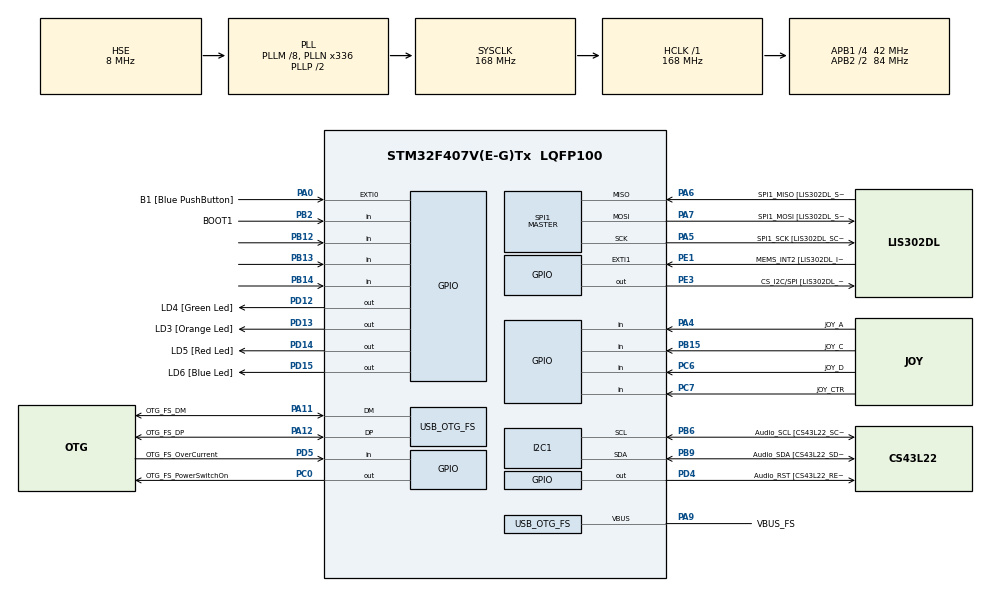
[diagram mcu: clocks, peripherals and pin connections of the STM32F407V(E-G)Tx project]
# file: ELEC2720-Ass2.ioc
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PA11.GPIO_Speed=GPIO_SPEED_FREQ_LOW
PD12.GPIO_Label=LD4 [Green Led]
PH0-OSC_IN.Signal=RCC_OSC_IN
PC10.GPIO_PuPd=GPIO_NOPULL
SPI1.VirtualType=VM_MASTER
PB10.GPIO_PuPd=GPIO_NOPULL
PA10.GPIO_PuPd=GPIO_NOPULL
PC12.Signal=I2S3_SD
PA14.GPIO_Label=SWCLK
PC6.GPIO_Label=JOY_D
PA6.GPIO_Label=SPI1_MISO [LIS302DL_SDO]
PB6.GPIO_Label=Audio_SCL [CS43L22_SCL]
PB13.Signal=GPIO_Input
PC15-OSC32_OUT.GPIO_Label=PC15-OSC32_OUT
PC3.GPIO_Speed=GPIO_SPEED_FREQ_LOW
RCC.SYSCLKSource=RCC_SYSCLKSOURCE_PLLCLK
PA6.GPIO_Mode=GPIO_MODE_AF_PP
PD14.GPIO_Speed=GPIO_SPEED_FREQ_LOW
SPI1.Direction=SPI_DIRECTION_2LINES
PD4.Signal=GPIO_Output
RCC.APB2TimFreq_Value=168000000
PB6.Signal=I2C1_SCL
PC7.Signal=GPIO_Input
PB6.Mode=I2C
PC3.Signal=I2S2_SD
PE1.Signal=GPXTI1
USB_OTG_FS.phy_itface=HCD_PHY_EMBEDDED
PB2.Signal=GPIO_Input
PA5.GPIO_PuPd=GPIO_NOPULL
PD5.GPIO_Mode=GPIO_MODE_INPUT
PD14.GPIO_PuPd=GPIO_NOPULL
PB2.GPIO_PuPd=GPIO_NOPULL
SPI1.CalculateBaudRate-Full_Duplex_Master=42.0 MBits/s
Mcu.Package=LQFP100
PB9.Signal=I2C1_SDA
PB14.GPIO_PuPd=GPIO_PULLUP
PD12.Signal=GPIO_Output
PB9.GPIO_PuPd=GPIO_NOPULL
PA10.Signal=USB_OTG_FS_ID
PC6.GPIO_PuPd=GPIO_PULLUP
RCC.APB2CLKDivider=RCC_HCLK_DIV2
RCC.APB1TimFreq_Value=84000000
PC12.GPIO_PuPd=GPIO_NOPULL
PA6.GPIO_Speed=GPIO_SPEED_FREQ_LOW
PA12.GPIO_PuPd=GPIO_NOPULL
PA4.GPIO_Label=JOY_A
PD15.Signal=GPIO_Output
PC0.PinState=GPIO_PIN_SET
PA5.Mode=Full_Duplex_Master
PA9.GPIO_Label=VBUS_FS
PB6.GPIO_PuPd=GPIO_NOPULL
PC6.Signal=GPIO_Input
PA11.GPIO_Label=OTG_FS_DM
PE1.GPIO_PuPd=GPIO_NOPULL
PC0.Signal=GPIO_Output
RCC.APB1CLKDivider=RCC_HCLK_DIV4
PC14-OSC32_IN.Signal=RCC_OSC32_IN
PA0-WKUP.GPIO_ModeDefaultEXTI=GPIO_MODE_EVT_RISING
PA0-WKUP.GPIO_Label=B1 [Blue PushButton]
PA0-WKUP.Signal=GPXTI0
USB_HOST0.BSP.STBoard=false
PC10.GPIO_Mode=GPIO_MODE_AF_PP
PB10.GPIO_Mode=GPIO_MODE_AF_PP
PA9.Signal=USB_OTG_FS_VBUS
PC7.GPIO_PuPd=GPIO_PULLUP
PB10.Signal=I2S2_CK
PB14.Signal=GPIO_Input
PA5.Signal=SPI1_SCK
PE1.GPIO_Label=MEMS_INT2 [LIS302DL_INT2]
USB_HOST.VirtualModeFS=Cdc
PA7.GPIO_Speed=GPIO_SPEED_FREQ_LOW
PB13.GPIO_PuPd=GPIO_PULLUP
PB2.GPIO_Mode=GPIO_MODE_INPUT
PB15.GPIO_Label=JOY_C
SPI1.Mode=SPI_MODE_MASTER
PD4.GPIO_Speed=GPIO_SPEED_FREQ_LOW
PE3.GPIO_PuPd=GPIO_NOPULL
PH1-OSC_OUT.GPIO_Label=PH1-OSC_OUT
PA13.Mode=Serial_Wire
PC7.GPIO_Label=JOY_CTR
PA4.Signal=GPIO_Input
PC12.GPIO_Mode=GPIO_MODE_AF_PP
PA5.GPIO_Label=SPI1_SCK [LIS302DL_SCL/SPC]
PE3.GPIO_Speed=GPIO_SPEED_FREQ_LOW
PC12.GPIO_Label=I2S3_SD [CS43L22_SDIN]
PA11.Signal=USB_OTG_FS_DM
ProjectManager.HeapSize=0x200
NVIC.PriorityGroup=NVIC_PRIORITYGROUP_0
PE3.Signal=GPIO_Output
PC3.GPIO_Label=PDM_OUT [MP45DT02_DOUT]
PA0-WKUP.GPIO_PuPd=GPIO_NOPULL
PB6.GPIO_Speed=GPIO_SPEED_FREQ_LOW
SPI1.BaudRatePrescaler-Full_Duplex_Master=SPI_BAUDRATEPRESCALER_2
USB_HOST0.BSP.mode=Output
Mcu.Family=STM32F4
PC3.GPIO_Mode=GPIO_MODE_AF_PP
PA6.Mode=Full_Duplex_Master
RCC.CortexFreq_Value=168000000
PB10.GPIO_Speed=GPIO_SPEED_FREQ_LOW
PB6.GPIO_Mode=GPIO_MODE_AF_OD
PD15.GPIO_Speed=GPIO_SPEED_FREQ_LOW
PC10.Signal=I2S3_CK
PA7.GPIO_Mode=GPIO_MODE_AF_PP
PC0.GPIO_Label=OTG_FS_PowerSwitchOn
PA11.Mode=Host_Only
PC10.GPIO_Speed=GPIO_SPEED_FREQ_LOW
PA11.GPIO_PuPd=GPIO_NOPULL
PB15.Signal=GPIO_Input
ProjectManager.StackSize=0x400
SPI1.Mode-Full_Duplex_Master=SPI_MODE_MASTER
PD13.Signal=GPIO_Output
PA12.Signal=USB_OTG_FS_DP
RCC.HCLKFreq_Value=168000000
USB_HOST0.BSP.ip=GPIO
RCC.AHBFreq_Value=168000000
PH0-OSC_IN.Mode=HSE-External-Oscillator
PH0-OSC_IN.GPIO_Label=PH0-OSC_IN
PA9.GPIO_Mode=GPIO_MODE_INPUT
RCC.HSE_VALUE=8000000
PA4.GPIO_PuPd=GPIO_PULLUP
PA6.GPIO_PuPd=GPIO_NOPULL
PC14-OSC32_IN.Mode=LSE-External-Oscillator
PA14.Mode=Serial_Wire
PA10.GPIO_Label=OTG_FS_ID
USB_HOST0.BSP.i2creg=0
PH1-OSC_OUT.Mode=HSE-External-Oscillator
USB_HOST0.BSP.i2caddr=0
PD13.GPIO_Label=LD3 [Orange Led]
PA6.Signal=SPI1_MISO
PB15.GPIO_PuPd=GPIO_PULLUP
USB_HOST.USBH_HandleTypeDef-CDC_FS=hUsbHostFS
PD5.GPIO_Label=OTG_FS_OverCurrent
NVIC.OTG_FS_IRQn=true\:0\:0\:false\:false\:true\:true\:true
PD15.GPIO_PuPd=GPIO_NOPULL
USB_OTG_FS.VirtualMode=Host_Only
PA10.GPIO_Speed=GPIO_SPEED_FREQ_LOW
USB_HOST0.BSP.name=Drive_VBUS_FS
PB9.GPIO_Speed=GPIO_SPEED_FREQ_LOW
PC14-OSC32_IN.GPIO_Label=PC14-OSC32_IN
PC0.GPIO_PuPd=GPIO_NOPULL
PA12.GPIO_Speed=GPIO_SPEED_FREQ_LOW
PB3.GPIO_Label=SWO
PC15-OSC32_OUT.Mode=LSE-External-Oscillator
PD12.GPIO_Speed=GPIO_SPEED_FREQ_LOW
PD15.GPIO_Label=LD6 [Blue Led]
PA7.Mode=Full_Duplex_Master
PB9.GPIO_Label=Audio_SDA [CS43L22_SDA]
PC10.GPIO_Label=I2S3_SCK [CS43L22_SCLK]
USB_HOST0.BSP.solution=PC0
USB_HOST.BSP.number=1
PD5.Signal=GPIO_Input
PE1.GPIO_ModeDefaultEXTI=GPIO_MODE_EVT_RISING
PA9.GPIO_PuPd=GPIO_NOPULL
PA12.GPIO_Label=OTG_FS_DP
PA10.GPIO_Mode=GPIO_MODE_AF_PP
PA13.Signal=SYS_JTMS-SWDIO
PD4.GPIO_PuPd=GPIO_NOPULL
PA9.Mode=Activate_VBUS
PC0.GPIO_Speed=GPIO_SPEED_FREQ_LOW
ProjectManager.TargetToolchain=STM32CubeIDE
PB10.GPIO_Label=CLK_IN [MP45DT02_CLK]
PB9.Mode=I2C
PC15-OSC32_OUT.Signal=RCC_OSC32_OUT
PA7.GPIO_PuPd=GPIO_NOPULL
board=STM32F407G-DISC1
PD13.GPIO_Speed=GPIO_SPEED_FREQ_LOW
RCC.VCOOutputFreq_Value=336000000
PB9.GPIO_Mode=GPIO_MODE_AF_OD
PA12.GPIO_Mode=GPIO_MODE_AF_PP
RCC.APB2Freq_Value=84000000
USB_HOST0.BSP.api=Unknown
PD4.GPIO_Label=Audio_RST [CS43L22_RESET]
PH1-OSC_OUT.Signal=RCC_OSC_OUT
PD13.GPIO_PuPd=GPIO_NOPULL
PD5.GPIO_PuPd=GPIO_NOPULL
PD14.GPIO_Label=LD5 [Red Led]
Mcu.Name=STM32F407V(E-G)Tx
PA13.GPIO_Label=SWDIO
PD14.Signal=GPIO_Output
RCC.48MHZClocksFreq_Value=48000000
PB3.Signal=SYS_JTDO-SWO
RCC.SYSCLKFreq_VALUE=168000000
PA7.GPIO_Label=SPI1_MOSI [LIS302DL_SDA/SDI/SDO]
PA12.Mode=Host_Only
VP_USB_HOST_VS_USB_HOST_CDC_FS.Mode=CDC_FS
PA14.Signal=SYS_JTCK-SWCLK
PB2.GPIO_Label=BOOT1
RCC.HSI_VALUE=16000000
PA5.GPIO_Speed=GPIO_SPEED_FREQ_LOW
RCC.PLLQ=7
RCC.PLLM=8
RCC.PLLN=336
PE3.GPIO_Label=CS_I2C/SPI [LIS302DL_CS_I2C/SPI]
PA11.GPIO_Mode=GPIO_MODE_AF_PP
RCC.APB1Freq_Value=42000000
PA5.GPIO_Mode=GPIO_MODE_AF_PP
PC12.GPIO_Speed=GPIO_SPEED_FREQ_LOW
PB12.Signal=GPIO_Input
PC3.GPIO_PuPd=GPIO_NOPULL
PD12.GPIO_PuPd=GPIO_NOPULL
PA7.Signal=SPI1_MOSI
USB_HOST0.BSP.instance=PC0

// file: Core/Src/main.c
/* USER CODE BEGIN Header */
/**
  ******************************************************************************
  * @file           : main.c
  * @brief          : Main program body
  ******************************************************************************
  * @attention
  *
  * <h2><center>&copy; Copyright (c) 2022 STMicroelectronics.
  * All rights reserved.</center></h2>
  *
  * This software component is licensed by ST under Ultimate Liberty license
  * SLA0044, the "License"; You may not use this file except in compliance with
  * the License. You may obtain a copy of the License at:
  *                             www.st.com/SLA0044
  *
  ******************************************************************************
  */
/* USER CODE END Header */
#include "main.h"
#include "usb_host.h"

/* USER CODE BEGIN PD */
#define DEBOUNCE_INTERVAL 20
/* USER CODE END PD */

I2C_HandleTypeDef hi2c1;

SPI_HandleTypeDef hspi1;

void SystemClock_Config(void);
static void MX_GPIO_Init(void);
static void MX_I2C1_Init(void);
static void MX_SPI1_Init(void);
void MX_USB_HOST_Process(void);

int main(void)
{

  /* MCU Configuration--------------------------------------------------------*/

  /* Reset of all peripherals, Initializes the Flash interface and the Systick. */
  HAL_Init();

  /* Configure the system clock */
  SystemClock_Config();

  /* Initialize all configured peripherals */
  MX_GPIO_Init();
  MX_I2C1_Init();
  MX_SPI1_Init();
  MX_USB_HOST_Init();
  /* USER CODE BEGIN 2 */
  int debounce_counter = 0;
  enum debounceState {LOCKED, RELEASED};
  enum debounceState debounce_state = RELEASED;
  int JoyState = 1;

  /* USER CODE END 2 */
  HAL_GPIO_WritePin(LD4_GPIO_Port, LD4_Pin, 0); // Left LED
  HAL_GPIO_WritePin(LD5_GPIO_Port, LD5_Pin, 0); // Right LED

  /* Infinite loop */
  while (1)
  {
    MX_USB_HOST_Process();

    switch(debounce_state) {
    	case RELEASED:
    	// Read JOY_C only when RELEASED
			JoyState = HAL_GPIO_ReadPin (JOY_C_GPIO_Port, JOY_C_Pin);
			if (JoyState == 0) {
				debounce_state = LOCKED;
			}
		break;

    case LOCKED:
		JoyState = 1; // Manually reset JoyState when LOCKED
		if ( debounce_counter > DEBOUNCE_INTERVAL) {
			debounce_state = RELEASED; // RELEASE after time-out
			debounce_counter = 0;
		}
		else {
			++debounce_counter; // still LOCKED, increase counter
		}
		break;
    }

    if (HAL_GPIO_ReadPin(JOY_CTR_GPIO_Port, JOY_CTR_Pin) == 0) { // Joy Stick: Centre
         HAL_GPIO_WritePin(LD4_GPIO_Port, LD4_Pin, 0);
         HAL_GPIO_WritePin(LD5_GPIO_Port, LD5_Pin, 0);
       }
   	else if (HAL_GPIO_ReadPin(JOY_A_GPIO_Port, JOY_A_Pin) == 0) { // Joy Stick: Left
         HAL_GPIO_WritePin(LD4_GPIO_Port, LD4_Pin, 1);
         HAL_GPIO_WritePin(LD5_GPIO_Port, LD5_Pin, 0);
       }
   	else if (HAL_GPIO_ReadPin(JOY_D_GPIO_Port, JOY_D_Pin) == 0) { // Joy Stick: Right
         HAL_GPIO_WritePin(LD4_GPIO_Port, LD4_Pin, 0);
         HAL_GPIO_WritePin(LD5_GPIO_Port, LD5_Pin, 1);
   	}
   	else if (JoyState == 0) { // Joy Stick: Down
         if (HAL_GPIO_ReadPin(LD4_GPIO_Port, LD4_Pin) == 0 && HAL_GPIO_ReadPin(LD5_GPIO_Port, LD5_Pin) == 0) { // LEDs All off
           HAL_GPIO_WritePin(LD4_GPIO_Port, LD4_Pin, 1);
           HAL_GPIO_WritePin(LD5_GPIO_Port, LD5_Pin, 0);
         }
         else { // One led already on
           HAL_GPIO_TogglePin(LD4_GPIO_Port, LD4_Pin);
           HAL_GPIO_TogglePin(LD5_GPIO_Port, LD5_Pin);
         }
     }
    HAL_Delay(10);

  }
}

void SystemClock_Config(void)
{
  RCC_OscInitTypeDef RCC_OscInitStruct = {0};
  RCC_ClkInitTypeDef RCC_ClkInitStruct = {0};

  /** Configure the main internal regulator output voltage
  */
  __HAL_RCC_PWR_CLK_ENABLE();
  __HAL_PWR_VOLTAGESCALING_CONFIG(PWR_REGULATOR_VOLTAGE_SCALE1);
  /** Initializes the RCC Oscillators according to the specified parameters
  * in the RCC_OscInitTypeDef structure.
  */
  RCC_OscInitStruct.OscillatorType = RCC_OSCILLATORTYPE_HSE;
  RCC_OscInitStruct.HSEState = RCC_HSE_ON;
  RCC_OscInitStruct.PLL.PLLState = RCC_PLL_ON;
  RCC_OscInitStruct.PLL.PLLSource = RCC_PLLSOURCE_HSE;
  RCC_OscInitStruct.PLL.PLLM = 8;
  RCC_OscInitStruct.PLL.PLLN = 336;
  RCC_OscInitStruct.PLL.PLLP = RCC_PLLP_DIV2;
  RCC_OscInitStruct.PLL.PLLQ = 7;
  if (HAL_RCC_OscConfig(&RCC_OscInitStruct) != HAL_OK)
  {
    Error_Handler();
  }
  /** Initializes the CPU, AHB and APB buses clocks
  */
  RCC_ClkInitStruct.ClockType = RCC_CLOCKTYPE_HCLK|RCC_CLOCKTYPE_SYSCLK
                              |RCC_CLOCKTYPE_PCLK1|RCC_CLOCKTYPE_PCLK2;
  RCC_ClkInitStruct.SYSCLKSource = RCC_SYSCLKSOURCE_PLLCLK;
  RCC_ClkInitStruct.AHBCLKDivider = RCC_SYSCLK_DIV1;
  RCC_ClkInitStruct.APB1CLKDivider = RCC_HCLK_DIV4;
  RCC_ClkInitStruct.APB2CLKDivider = RCC_HCLK_DIV2;

  if (HAL_RCC_ClockConfig(&RCC_ClkInitStruct, FLASH_LATENCY_5) != HAL_OK)
  {
    Error_Handler();
  }
}

static void MX_I2C1_Init(void)
{

  hi2c1.Instance = I2C1;
  hi2c1.Init.ClockSpeed = 100000;
  hi2c1.Init.DutyCycle = I2C_DUTYCYCLE_2;
  hi2c1.Init.OwnAddress1 = 0;
  hi2c1.Init.AddressingMode = I2C_ADDRESSINGMODE_7BIT;
  hi2c1.Init.DualAddressMode = I2C_DUALADDRESS_DISABLE;
  hi2c1.Init.OwnAddress2 = 0;
  hi2c1.Init.GeneralCallMode = I2C_GENERALCALL_DISABLE;
  hi2c1.Init.NoStretchMode = I2C_NOSTRETCH_DISABLE;
  if (HAL_I2C_Init(&hi2c1) != HAL_OK)
  {
    Error_Handler();
  }

}

static void MX_SPI1_Init(void)
{

  /* SPI1 parameter configuration*/
  hspi1.Instance = SPI1;
  hspi1.Init.Mode = SPI_MODE_MASTER;
  hspi1.Init.Direction = SPI_DIRECTION_2LINES;
  hspi1.Init.DataSize = SPI_DATASIZE_8BIT;
  hspi1.Init.CLKPolarity = SPI_POLARITY_LOW;
  hspi1.Init.CLKPhase = SPI_PHASE_1EDGE;
  hspi1.Init.NSS = SPI_NSS_SOFT;
  hspi1.Init.BaudRatePrescaler = SPI_BAUDRATEPRESCALER_2;
  hspi1.Init.FirstBit = SPI_FIRSTBIT_MSB;
  hspi1.Init.TIMode = SPI_TIMODE_DISABLE;
  hspi1.Init.CRCCalculation = SPI_CRCCALCULATION_DISABLE;
  hspi1.Init.CRCPolynomial = 10;
  if (HAL_SPI_Init(&hspi1) != HAL_OK)
  {
    Error_Handler();
  }

}

static void MX_GPIO_Init(void)
{
  GPIO_InitTypeDef GPIO_InitStruct = {0};

  /* GPIO Ports Clock Enable */
  __HAL_RCC_GPIOE_CLK_ENABLE();
  __HAL_RCC_GPIOC_CLK_ENABLE();
  __HAL_RCC_GPIOH_CLK_ENABLE();
  __HAL_RCC_GPIOA_CLK_ENABLE();
  __HAL_RCC_GPIOB_CLK_ENABLE();
  __HAL_RCC_GPIOD_CLK_ENABLE();

  /*Configure GPIO pin Output Level */
  HAL_GPIO_WritePin(CS_I2C_SPI_GPIO_Port, CS_I2C_SPI_Pin, GPIO_PIN_RESET);

  /*Configure GPIO pin Output Level */
  HAL_GPIO_WritePin(OTG_FS_PowerSwitchOn_GPIO_Port, OTG_FS_PowerSwitchOn_Pin, GPIO_PIN_SET);

  /*Configure GPIO pin Output Level */
  HAL_GPIO_WritePin(GPIOD, LD4_Pin|LD3_Pin|LD5_Pin|LD6_Pin
                          |Audio_RST_Pin, GPIO_PIN_RESET);

  /*Configure GPIO pin : CS_I2C_SPI_Pin */
  GPIO_InitStruct.Pin = CS_I2C_SPI_Pin;
  GPIO_InitStruct.Mode = GPIO_MODE_OUTPUT_PP;
  GPIO_InitStruct.Pull = GPIO_NOPULL;
  GPIO_InitStruct.Speed = GPIO_SPEED_FREQ_LOW;
  HAL_GPIO_Init(CS_I2C_SPI_GPIO_Port, &GPIO_InitStruct);

  /*Configure GPIO pin : OTG_FS_PowerSwitchOn_Pin */
  GPIO_InitStruct.Pin = OTG_FS_PowerSwitchOn_Pin;
  GPIO_InitStruct.Mode = GPIO_MODE_OUTPUT_PP;
  GPIO_InitStruct.Pull = GPIO_NOPULL;
  GPIO_InitStruct.Speed = GPIO_SPEED_FREQ_LOW;
  HAL_GPIO_Init(OTG_FS_PowerSwitchOn_GPIO_Port, &GPIO_InitStruct);

  /*Configure GPIO pin : PDM_OUT_Pin */
  GPIO_InitStruct.Pin = PDM_OUT_Pin;
  GPIO_InitStruct.Mode = GPIO_MODE_AF_PP;
  GPIO_InitStruct.Pull = GPIO_NOPULL;
  GPIO_InitStruct.Speed = GPIO_SPEED_FREQ_LOW;
  GPIO_InitStruct.Alternate = GPIO_AF5_SPI2;
  HAL_GPIO_Init(PDM_OUT_GPIO_Port, &GPIO_InitStruct);

  /*Configure GPIO pin : B1_Pin */
  GPIO_InitStruct.Pin = B1_Pin;
  GPIO_InitStruct.Mode = GPIO_MODE_EVT_RISING;
  GPIO_InitStruct.Pull = GPIO_NOPULL;
  HAL_GPIO_Init(B1_GPIO_Port, &GPIO_InitStruct);

  /*Configure GPIO pin : JOY_A_Pin */
  GPIO_InitStruct.Pin = JOY_A_Pin;
  GPIO_InitStruct.Mode = GPIO_MODE_INPUT;
  GPIO_InitStruct.Pull = GPIO_PULLUP;
  HAL_GPIO_Init(JOY_A_GPIO_Port, &GPIO_InitStruct);

  /*Configure GPIO pins : BOOT1_Pin PB12 */
  GPIO_InitStruct.Pin = BOOT1_Pin|GPIO_PIN_12;
  GPIO_InitStruct.Mode = GPIO_MODE_INPUT;
  GPIO_InitStruct.Pull = GPIO_NOPULL;
  HAL_GPIO_Init(GPIOB, &GPIO_InitStruct);

  /*Configure GPIO pin : CLK_IN_Pin */
  GPIO_InitStruct.Pin = CLK_IN_Pin;
  GPIO_InitStruct.Mode = GPIO_MODE_AF_PP;
  GPIO_InitStruct.Pull = GPIO_NOPULL;
  GPIO_InitStruct.Speed = GPIO_SPEED_FREQ_LOW;
  GPIO_InitStruct.Alternate = GPIO_AF5_SPI2;
  HAL_GPIO_Init(CLK_IN_GPIO_Port, &GPIO_InitStruct);

  /*Configure GPIO pins : PB13 PB14 JOY_C_Pin */
  GPIO_InitStruct.Pin = GPIO_PIN_13|GPIO_PIN_14|JOY_C_Pin;
  GPIO_InitStruct.Mode = GPIO_MODE_INPUT;
  GPIO_InitStruct.Pull = GPIO_PULLUP;
  HAL_GPIO_Init(GPIOB, &GPIO_InitStruct);

  /*Configure GPIO pins : LD4_Pin LD3_Pin LD5_Pin LD6_Pin
                           Audio_RST_Pin */
  GPIO_InitStruct.Pin = LD4_Pin|LD3_Pin|LD5_Pin|LD6_Pin
                          |Audio_RST_Pin;
  GPIO_InitStruct.Mode = GPIO_MODE_OUTPUT_PP;
  GPIO_InitStruct.Pull = GPIO_NOPULL;
  GPIO_InitStruct.Speed = GPIO_SPEED_FREQ_LOW;
  HAL_GPIO_Init(GPIOD, &GPIO_InitStruct);

  /*Configure GPIO pins : JOY_D_Pin JOY_CTR_Pin */
  GPIO_InitStruct.Pin = JOY_D_Pin|JOY_CTR_Pin;
  GPIO_InitStruct.Mode = GPIO_MODE_INPUT;
  GPIO_InitStruct.Pull = GPIO_PULLUP;
  HAL_GPIO_Init(GPIOC, &GPIO_InitStruct);

  /*Configure GPIO pins : I2S3_SCK_Pin I2S3_SD_Pin */
  GPIO_InitStruct.Pin = I2S3_SCK_Pin|I2S3_SD_Pin;
  GPIO_InitStruct.Mode = GPIO_MODE_AF_PP;
  GPIO_InitStruct.Pull = GPIO_NOPULL;
  GPIO_InitStruct.Speed = GPIO_SPEED_FREQ_LOW;
  GPIO_InitStruct.Alternate = GPIO_AF6_SPI3;
  HAL_GPIO_Init(GPIOC, &GPIO_InitStruct);

  /*Configure GPIO pin : OTG_FS_OverCurrent_Pin */
  GPIO_InitStruct.Pin = OTG_FS_OverCurrent_Pin;
  GPIO_InitStruct.Mode = GPIO_MODE_INPUT;
  GPIO_InitStruct.Pull = GPIO_NOPULL;
  HAL_GPIO_Init(OTG_FS_OverCurrent_GPIO_Port, &GPIO_InitStruct);

  /*Configure GPIO pin : MEMS_INT2_Pin */
  GPIO_InitStruct.Pin = MEMS_INT2_Pin;
  GPIO_InitStruct.Mode = GPIO_MODE_EVT_RISING;
  GPIO_InitStruct.Pull = GPIO_NOPULL;
  HAL_GPIO_Init(MEMS_INT2_GPIO_Port, &GPIO_InitStruct);

}

void Error_Handler(void)
{
  __disable_irq();
  while (1)
  {
  }
}

/************************ (C) COPYRIGHT STMicroelectronics *****END OF FILE****/
